# R7FA2A1AB register map
Vendor: Renesas; Series: RA2; File version: 1.1
CPU: CM23 r1p0, little endian, MPU, no FPU, VTOR, 2 interrupt priority bits
Registers are 8-bit, read-write, reset 0x0 unless marked. A register's access mark holds for its fields unless they carry their own. Offsets are from the block's base; [hi:lo] are bit positions; lines under a group give offsets from that group; {n}, {i} and the like mark numbered series; 'fields as' and 'values as' point back to an identical list.

## ADC160 — 16-bit A/D Converter
Base 0x4005C000
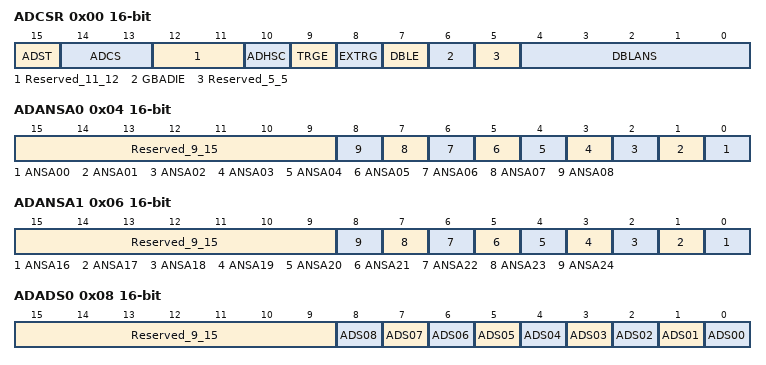
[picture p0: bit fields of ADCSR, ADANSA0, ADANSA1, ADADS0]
0x00 ADCSR 16-bit — A/D Control Register
  [15] ADST read-modifies — A/D Conversion Start
  [14:13] ADCS — Scan Mode Select
  [12:11] Reserved_11_12 — These bits are read as 00. The write value should be 00.
  [10] ADHSC — A/D Conversion Operation Mode Select
  [9] TRGE — Trigger Start Enable
  [8] EXTRG — Trigger Select
  [7] DBLE — Double Trigger Mode Select
  [6] GBADIE — Group B Scan End Interrupt Enable
  [5] Reserved_5_5 — This bit is read as 0. The write value should be 0.
  [4:0] DBLANS — Double Trigger Channel SelectThese bits select one analog input channel for double triggered operation. The setting is only effective while double trigger mode is selected.
0x04 ADANSA0 16-bit — A/D Channel Select Register A0
  [15:9] Reserved_9_15 — These bits are read as 0000000. The write value should be 0000000.
  [n] ANSA{n:02} (n=0..8) — AN{n:03} Select
0x06 ADANSA1 16-bit — A/D Channel Select Register A1
  [15:9] Reserved_9_15 — These bits are read as 0000000. The write value should be 0000000.
  [n-16] ANSA{n} (n=16..24) — AN{n:03} Select
0x08 ADADS0 16-bit — A/D,Converted Value Average Channel Select Register 0
  [15:9] Reserved_9_15 — These bits are read as 0000000. The write value should be 0000000.
  [n] ADS{n:02} (n=0..8) — A/D,Converted Value Average Channel AN{n:03} Select
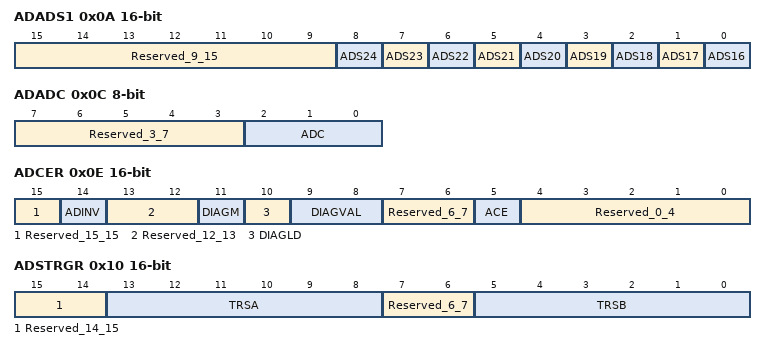
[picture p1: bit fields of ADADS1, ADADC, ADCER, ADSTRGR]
0x0A ADADS1 16-bit — A/D,Converted Value Average Channel Select Register 1
  [15:9] Reserved_9_15 — These bits are read as 0000000. The write value should be 0000000.
  [n-16] ADS{n} (n=16..24) — A/D,Converted Value Average Channel AN{n:03} Select
0x0C ADADC — A/D,Converted Value Average Count Select Register
  [7:3] Reserved_3_7 — These bits are read as 00000. The write value should be 00000.
  [2:0] ADC — Count Select
0x0E ADCER 16-bit — A/D Control Extended Register
  [15] Reserved_15_15 — This bit is read as 0. The write value should be 0.
  [14] ADINV — Single,End Input A/D Converted Data Inversion Select
  [13:12] Reserved_12_13 — These bits are read as 00. The write value should be 00.
  [11] DIAGM — Self,Diagnosis Enable
  [10] DIAGLD — Self,Diagnosis Mode Select
  [9:8] DIAGVAL — Self,Diagnosis Conversion Voltage Select
  [7:6] Reserved_6_7 — These bits are read as 00. The write value should be 00.
  [5] ACE — A/D Data Register Automatic Clearing Enable
  [4:0] Reserved_0_4 — These bits are read as 00000. The write value should be 00000.
0x10 ADSTRGR 16-bit — A/D Conversion Start Trigger Select Register
  [15:14] Reserved_14_15 — These bits are read as 00. The write value should be 00.
  [13:8] TRSA — A/D Conversion Start Trigger SelectSelect the A/D conversion start trigger in single scan mode and continuous mode. In group scan mode, the A/D conversion start trigger for group A is selected.
  [7:6] Reserved_6_7 — These bits are read as 00. The write value should be 00.
  [5:0] TRSB — A/D Conversion Start Trigger Select for Group BSelect the A/D conversion start trigger for group B in group scan mode.
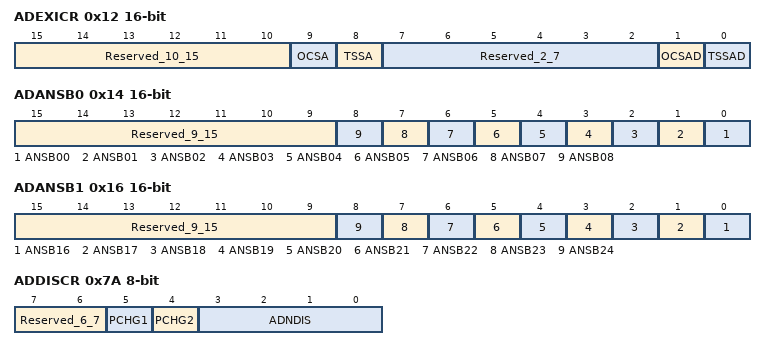
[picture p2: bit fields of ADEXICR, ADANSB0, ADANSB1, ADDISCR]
0x12 ADEXICR 16-bit — A/D Conversion Extended Input Control Register
  [15:10] Reserved_10_15 — These bits are read as 000000. The write value should be 000000.
  [9] OCSA — Internal Reference Voltage A/D Conversion Select
  [8] TSSA — Temperature Sensor Output A/D Conversion Select
  [7:2] Reserved_2_7 — These bits are read as 000000. The write value should be 000000.
  [1] OCSAD — Internal Reference Voltage A/D converted Value Average Mode Select
  [0] TSSAD — Temperature Sensor Output A/D converted Value Average Mode Select
0x14 ADANSB0 16-bit — A/D Channel Select Register B0
  [15:9] Reserved_9_15 — These bits are read as 0000000. The write value should be 0000000.
  [n] ANSB{n:02} (n=0..8) — AN{n:03} Select
0x16 ADANSB1 16-bit — A/D Channel Select Register B1
  [15:9] Reserved_9_15 — These bits are read as 0000000. The write value should be 0000000.
  [n-16] ANSB{n} (n=16..24) — AN{n:03} Select
0x18 ADDBLDR 16-bit ro — A/D Data Duplexing Register
  [15:0] ADDBLDR — This is a 16-bit read,only register for storing the result of A/D conversion in response to the second trigger in double trigger mode.
0x1A ADTSDR 16-bit ro — A/D Temperature Sensor Data Register
  [15:0] ADTSDR — This is a 16-bit read,only register for storing the A/D conversion result of temperature sensor output.
0x1C ADOCDR 16-bit ro — A/D Internal Reference Voltage Data Register
  [15:0] ADOCDR — This is a 16-bit read,only register for storing the A/D result of internal reference voltage.
{0x20+2i} ADDR{i} (i=0..8) 16-bit ro — A/D Data Register {i}
  [15:0] ADDR — The ADDR register is a 16-bit read,only registers for storing the result of A/D conversion.
{0x20+2i} ADDR{i}_1 (i=16..24) 16-bit ro — A/D Data Register {i}
  fields as ADDR0
0x7A ADDISCR — A/D Disconnection Detection Control Register
  [7:6] Reserved_6_7 — These bits are read as 00. The write value should be 00.
  [5] PCHG1 — Precharge/discharge select for even analog input channels from AN000 to AN008 or analog input channels from AN016 to AN023
  [4] PCHG2 — Precharge/discharge select for odd analog input channels from AN000 to AN007
  [3:0] ADNDIS — Precharg/discharge period
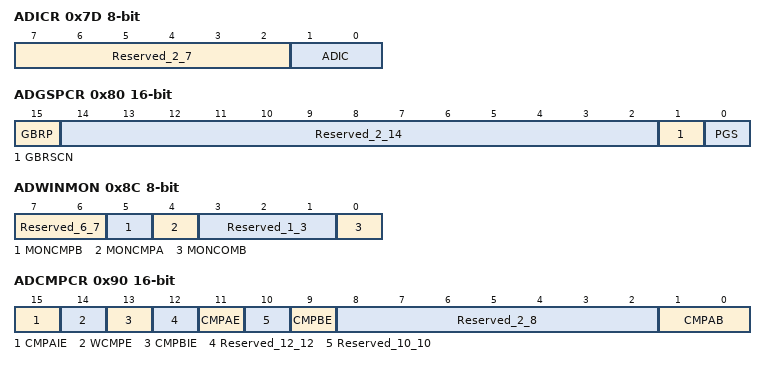
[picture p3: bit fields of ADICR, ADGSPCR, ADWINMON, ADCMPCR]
0x7D ADICR — A/D Interrupt Control Register
  [7:2] Reserved_2_7 — These bits are read as 000000. The write value should be 000000.
  [1:0] ADIC — A/D Interrupt Control
0x80 ADGSPCR 16-bit — A/D Group Scan Priority Control Register
  [15] GBRP — Group B Single Scan Continuous Start(Enabled only when PGS = 1. Reserved when PGS = 0.)Note: When the GBRP bit has been set to 1, single scan is performed continuously for group B regardless of the setting of the GBRSCN bit.
  [14:2] Reserved_2_14 — These bits are read as 0000000000000. The write value should be 0000000000000.
  [1] GBRSCN — Group B Restart Setting(Enabled only when PGS = 1. Reserved when PGS = 0.)
  [0] PGS — Group A priority control setting bit.Note: When the PGS bit is to be set to 1, the ADCSR.ADCS[1:0] bits must be set to 01b (group scan mode). If the bits are set to any other values, proper operation is not guaranteed.
0x84 ADDBLDRA 16-bit ro — A/D Data Duplexing Register A
  [15:0] ADDBLDRA — This register is a 16-bit read,only registers for storing the result of A/D conversion in response to the respective triggers during extended operation in double trigger mode.
0x86 ADDBLDRB 16-bit ro — A/D Data Duplexing Register B
  [15:0] ADDBLDRB — This register is a 16-bit read,only registers for storing the result of A/D conversion in response to the respective triggers during extended operation in double trigger mode.
0x8C ADWINMON ro — A/D Compare Function Window A/B Status Monitor Register
  [7:6] Reserved_6_7 — These bits are read as 00.
  [5] MONCMPB — Comparison Result Monitor B
  [4] MONCMPA — Comparison Result Monitor A
  [3:1] Reserved_1_3 — These bits are read as 000.
  [0] MONCOMB — Combination result monitorThis bit indicates the combination result. This bit is valid when both window A operation and window B operation are enabled.
0x90 ADCMPCR 16-bit — A/D Compare Function Control Register
  [15] CMPAIE — Compare A Interrupt Enable
  [14] WCMPE — Window Function Setting
  [13] CMPBIE — Compare B Interrupt Enable
  [12] Reserved_12_12 — This bit is read as 0. The write value should be 0.
  [11] CMPAE — Compare Window A Operation Enable
  [10] Reserved_10_10 — This bit is read as 0. The write value should be 0.
  [9] CMPBE — Compare Window B Operation Enable
  [8:2] Reserved_2_8 — These bits are read as 0000000. The write value should be 0000000.
  [1:0] CMPAB — Window A/B Composite Conditions SettingNOTE: These bits are valid when both window A and window B are enabled (CMPAE = 1 and CMPBE = 1).
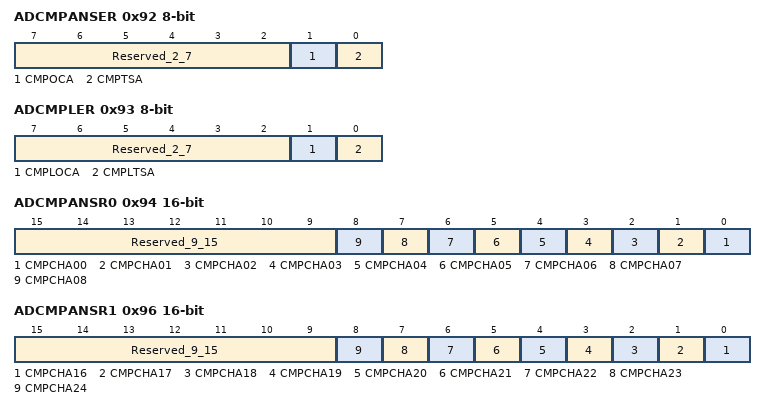
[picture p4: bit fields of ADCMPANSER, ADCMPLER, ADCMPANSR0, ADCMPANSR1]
0x92 ADCMPANSER — A/D Compare Function Window A Extended Input Select Register
  [7:2] Reserved_2_7 — These bits are read as 000000. The write value should be 000000.
  [1] CMPOCA — Internal reference voltage Compare selection bit.
  [0] CMPTSA — Temperature sensor output Compare selection bit.
0x93 ADCMPLER — A/D Compare Function Window A Extended Input Comparison Condition Setting Register
  [7:2] Reserved_2_7 — These bits are read as 000000. The write value should be 000000.
  [1] CMPLOCA — Compare Window A Internal Reference Voltage ComparisonCondition Select
  [0] CMPLTSA — Compare Window A Temperature Sensor Output Comparison Condition Select
0x94 ADCMPANSR0 16-bit — A/D Compare Function Window A Channel Select Register 0
  [15:9] Reserved_9_15 — These bits are read as 0000000. The write value should be 0000000.
  [n] CMPCHA{n:02} (n=0..8) — AN{n:03} Select
0x96 ADCMPANSR1 16-bit — A/D Compare Function Window A Channel Select Register 1
  [15:9] Reserved_9_15 — These bits are read as 0000000. The write value should be 0000000.
  [n-16] CMPCHA{n} (n=16..24) — AN{n:03} Select
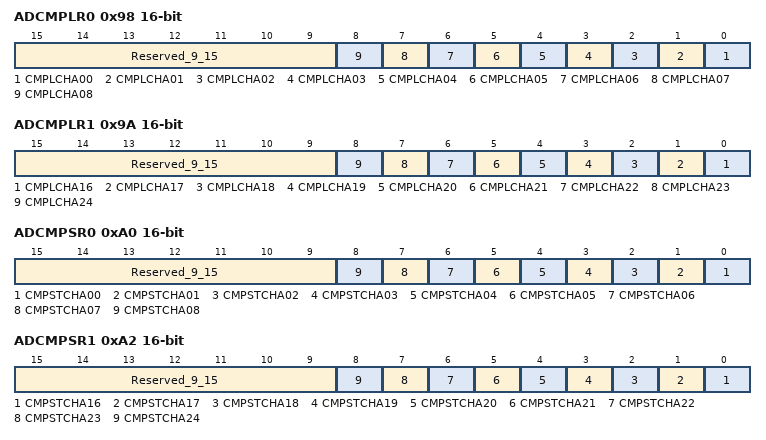
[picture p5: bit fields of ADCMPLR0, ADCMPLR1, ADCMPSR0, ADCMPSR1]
0x98 ADCMPLR0 16-bit — A/D Compare Function Window A Comparison Condition Setting Register 0
  [15:9] Reserved_9_15 — These bits are read as 0000000. The write value should be 0000000.
  [n] CMPLCHA{n:02} (n=0..8) — Comparison condition of AN{n:03}
0x9A ADCMPLR1 16-bit — A/D Compare Function Window A Comparison Condition Setting Register 1
  [15:9] Reserved_9_15 — These bits are read as 0000000. The write value should be 0000000.
  [n-16] CMPLCHA{n} (n=16..24) — Comparison condition for AN{n:03}
0x9C ADCMPDR0 16-bit — A/D Compare Function Window A Lower,Side Level Setting Register
  [15:0] ADCMPDR0 — The ADCMPDR0 register sets the reference data when the compare window A function is used. ADCMPDR0 sets the lower,side level of window A.
0x9E ADCMPDR1 16-bit — A/D Compare Function Window A Upper,Side Level Setting Register
  [15:0] ADCMPDR1 — The ADCMPDR1 register sets the reference data when the compare window A function is used. ADCMPDR1 sets the upper,side level of window A.
0xA0 ADCMPSR0 16-bit — A/D Compare Function Window A Channel Status Register 0
  [15:9] Reserved_9_15 — These bits are read as 0000000. The write value should be 0000000.
  [n] CMPSTCHA{n:02} write-0-clears read-modifies (n=0..8) — Compare window A flag for AN{n:03}
0xA2 ADCMPSR1 16-bit — A/D Compare Function Window A Channel Status Register 1
  [15:9] Reserved_9_15 — These bits are read as 0000000. The write value should be 0000000.
  [n-16] CMPSTCHA{n} write-0-clears read-modifies (n=16..24) — Compare window A flag for AN{n:03}
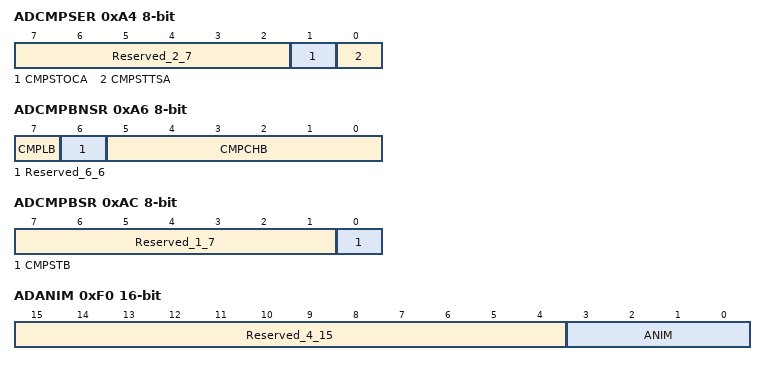
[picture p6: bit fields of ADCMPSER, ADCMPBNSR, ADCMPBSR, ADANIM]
0xA4 ADCMPSER — A/D Compare Function Window A Extended Input Channel Status Register
  [7:2] Reserved_2_7 — These bits are read as 000000. The write value should be 000000.
  [1] CMPSTOCA write-0-clears read-modifies — Compare Window A Internal Reference Voltage Compare Flag When window A operation is enabled (ADCMPCR.CMPAE = 1b), this bit indicates the temperature sensor output comparison result. When window A operation is disabled (ADCMPCR.CMPAE = 0b), comparison conditions for CMPSTTSA are not met any time.
  [0] CMPSTTSA write-0-clears read-modifies — Compare Window A Temperature Sensor Output Compare Flag When window A operation is enabled (ADCMPCR.CMPAE = 1b), this bit indicates the temperature sensor output comparison result. When window A operation is disabled (ADCMPCR.CMPAE = 0b), comparison conditions for CMPSTTSA are not met any time.
0xA6 ADCMPBNSR — A/D Compare Function Window B Channel Selection Register
  [7] CMPLB — Compare window B Compare condition setting bit.
  [6] Reserved_6_6 — This bit is read as 0. The write value should be 0.
  [5:0] CMPCHB — Compare window B channel selection bit.The channel that compares it on the condition of compare window B is selected.
0xA8 ADWINLLB 16-bit — A/D Compare Function Window B Lower,Side Level Setting Register
  [15:0] ADWINLLB — This register is used to compare A window function is used to set the lower level of the window B.
0xAA ADWINULB 16-bit — A/D Compare Function Window B Upper,Side Level Setting Register
  [15:0] ADWINULB — This register is used to compare A window function is used to set the higher level of the window B.
0xAC ADCMPBSR — A/D Compare Function Window B Status Register
  [7:1] Reserved_1_7 — These bits are read as 0000000. The write value should be 0000000.
  [0] CMPSTB write-0-clears read-modifies — Compare window B flagWhen window B operation is enabled (ADCMPCR.CMPBE = 1), this bit indicates the comparison result of channels AN000 to AN008, AN016 to AN023, reference voltage of SDADC24 (SBIAS/VREFI), temperature sensor output, and internal reference voltage to which window B comparison conditions are applied.
0xDD ADSSTRL reset 0xD — A/D Sampling State Register L
  [7:0] SST range 0x05..0xFF — Sampling Time Setting (AN016-AN023, SBIAS/VREFI)
0xDE ADSSTRT reset 0xD — A/D Sampling State Register T
  [7:0] SST range 0x05..0xFF — Sampling Time Setting (Temperature sensor output)
0xDF ADSSTRO reset 0xD — A/D Sampling State Register O
  [7:0] SST range 0x05..0xFF — Sampling Time Setting (Internal reference voltage)
{0xE0+i} ADSSTR0{i} (i=0..8) reset 0xD — A/D Sampling State Register {i}
  [7:0] SST range 0x05..0xFF — Sampling time setting
0xF0 ADANIM 16-bit — A/D Channel Input Mode Select Register
  [15:4] Reserved_4_15 — These bits are read as 000000000000. The write value should be 000000000000.
  [3:0] ANIM — Analog Channel Input Mode Select
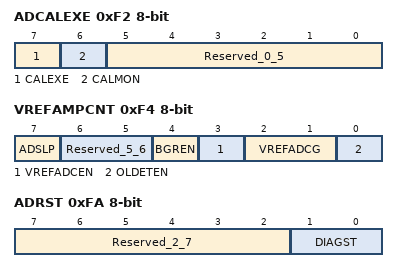
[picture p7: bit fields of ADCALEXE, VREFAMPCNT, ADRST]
0xF2 ADCALEXE — A/D Calibration Execution Register
  [7] CALEXE — Calibration Start
  [6] CALMON ro — Calibration Status Flag
  [5:0] Reserved_0_5 — These bits are read as 000000. The write value should be 000000.
0xF4 VREFAMPCNT — A/D Dedicated Reference Voltage Circuit Control Register
  [7] ADSLP — Sleep
  [6:5] Reserved_5_6 — These bits are read as 00. The write value should be 00.
  [4] BGREN — Low,Potential Reference Voltage Select
  [3] VREFADCEN — VREFADCG Enable
  [2:1] VREFADCG — VREFADC Output Voltage Control
  [0] OLDETEN — OLDET Enable
0xF8 ADRD 16-bit ro — A/D Self,Diagnosis Data Register
  [15:0] ADRD — The ADRD register is a 16-bit read,only register that holds the A/D conversion results based on the self,diagnosis of the ADC16.
0xFA ADRST — A/D Self,Diagnostic Status Register
  [7:2] Reserved_2_7 — These bits are read as 000000. The write value should be 000000.
  [1:0] DIAGST — Self,Diagnosis Status
